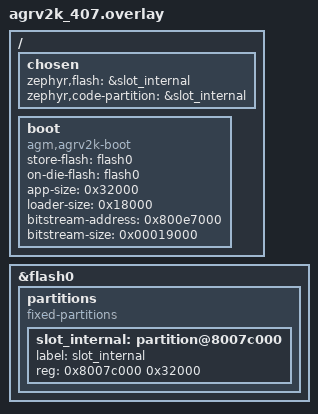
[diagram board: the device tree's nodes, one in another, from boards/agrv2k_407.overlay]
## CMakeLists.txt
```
# SPDX-License-Identifier: Apache-2.0

cmake_minimum_required(VERSION 3.28.0)
find_package(Zephyr REQUIRED HINTS $ENV{ZEPHYR_BASE})
project(usb_msc_dfu_boot)

# Reuse the upstream USB sample common code (sample_usbd.h +
# sample_usbd_init.c) instead of forking it into hal_ag32.
include(${ZEPHYR_BASE}/samples/subsys/usb/common/common.cmake)

FILE(GLOB app_sources src/*.c)
target_sources(app PRIVATE ${app_sources})
```

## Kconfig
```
# SPDX-License-Identifier: Apache-2.0

# Pull in the upstream USB sample options (SAMPLE_USBD_PID,
# SAMPLE_USBD_PRODUCT, SAMPLE_USBD_VID, ...) so prj.conf can set them.
# The `source` path is relative to $ZEPHYR_HOME/zephyr (`$ZEPHYR_BASE`).
source "samples/subsys/usb/common/Kconfig.sample_usbd"

source "Kconfig.zephyr"
```

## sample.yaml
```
# SPDX-License-Identifier: Apache-2.0
sample:
  name: usb_msc_dfu_boot
  description: |
    UF2-style USB MSC upload channel for samples/spi_boot_loader's DFU.

    A payload image (linked XIP into the loader's on-die application slot,
    like samples/spi_boot_app) that publishes a fake 64 MiB FAT16 volume so a
    host can copy a .uf2 onto a drive. Each 512 B write is parsed as a UF2
    block and its payload streamed straight into the loader's A/B store
    through the boot driver; the last block closes the MSC interface and the
    board reboots. It is the USB MSC path next to the loader's console /
    AN3155 / mcumgr upload paths, modelled on a UF2 bootloader.

    Hardware-dependent (needs the loader, the bitstream routing and a USB
    host), so the cases are build_only.
tests:
  sample.usb_msc_dfu_boot.agm_agrv2k_407:
    build_only: true
    platform_allow:
      - agrv2k_407
    integration_platforms:
      - agrv2k_407
    tags:
      - ci_build
      - hal_ag32
      - usb
      - udc
      - msc
      - dfu
      - boot
```

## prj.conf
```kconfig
# SPDX-License-Identifier: Apache-2.0
#
# UF2-style USB MSC upload channel for the spi_boot_loader DFU (agrv2k_407).
#
# This image is a payload that runs from the loader's on-die application
# slot. It publishes a fake 64 MiB FAT16 volume (src/uf2_volume.h) so a host
# mounts a drive and copies a .uf2 onto it; the sample parses the writes as a
# UF2 block stream and pushes the payload straight into the loader's A/B
# store through the boot driver's upload API (agm_boot_upload_begin/write/
# finish), closes the MSC interface and reboots. Model: a UF2 bootloader.
#
# It is the "USB MSC" upload path next to the loader's console / AN3155 /
# mcumgr paths (docs/BOOT-DFU-STATUS.md 0.1, the update section). No file
# system, no flash staging area, no image in SRAM.

# XIP into the on-die application slot the loader owns; see
# boards/agrv2k_407.overlay and samples/spi_boot_app.
CONFIG_XIP=y
CONFIG_USE_DT_CODE_PARTITION=y

# Chain-loaded image: the loader already brought the fabric up and switched
# the CPU onto the bitstream's PLL. Repeating soc.c's bring-up would
# deactivate the fabric this image is clocked from.
CONFIG_AGM_SOC_SKIP_CLOCK_INIT=y

CONFIG_SERIAL=y
CONFIG_UART_CONSOLE=y
CONFIG_PRINTK=y
CONFIG_STDOUT_CONSOLE=y

# The boot driver (drivers/misc/boot_agm.c) and the on-die flash it writes
# the stores through.
CONFIG_FLASH=y
CONFIG_FLASH_AGM=y
CONFIG_FLASH_PAGE_LAYOUT=y
CONFIG_CRC=y
CONFIG_REBOOT=y

# The USB side: a single MSC LUN backed by the sample's own fake FAT volume
# (registered at runtime with disk_access_register(), see src/main.c).
CONFIG_USB_DEVICE_STACK_NEXT=y
CONFIG_USBD_MSC_CLASS=y
CONFIG_DISK_ACCESS=y

# The UF2 block handler runs in the MSC class thread and calls into the boot
# driver's upload API (which erases/programs the store), so give that thread
# room beyond the 1024-byte default.
CONFIG_USBD_MSC_STACK_SIZE=4096

CONFIG_LOG=y
CONFIG_USBD_LOG_LEVEL_WRN=y
CONFIG_USBD_MSC_LOG_LEVEL_WRN=y
CONFIG_UDC_DRIVER_LOG_LEVEL_WRN=y

CONFIG_SAMPLE_USBD_PID=0x0008
CONFIG_SAMPLE_USBD_PRODUCT="AgRV2K USB MSC DFU (boot)"

# udc_agm is FS-only (64 B bulk MPS).
CONFIG_USBD_MAX_SPEED_FULL=y

# No HWINFO -> no iSerialNumber descriptor.
CONFIG_HWINFO=n

CONFIG_SAMPLE_USBD_SELF_POWERED=n
CONFIG_SAMPLE_USBD_REMOTE_WAKEUP=n
CONFIG_SAMPLE_USBD_MAX_POWER=50

CONFIG_MAIN_STACK_SIZE=3072
```

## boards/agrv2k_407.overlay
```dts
/* SPDX-License-Identifier: Apache-2.0 */
/*
 * usb_msc_dfu_boot -- the USB MSC upload channel for spi_boot_loader's DFU.
 *
 * Two things are configured here:
 *
 *   1. The link address: this image runs from the loader's on-die
 *      application slot, exactly like samples/spi_boot_app. Pointing
 *      /chosen/zephyr,flash at the slot partition is what moves the RISC-V
 *      link address (0x8007c000 with the default layout); the loader writes
 *      the image into that slot and jumps to it.
 *
 *   2. The boot layout: the boot driver derives every store/record offset
 *      from the boot node, so this sample has to describe the *same* layout
 *      the loader owns (samples/spi_boot_loader/boards/agrv2k_407.overlay).
 *      It uses agm_boot_upload_* on the store the loader's record does not
 *      point at, then the loader boots what it published.
 */

&flash0 {
	partitions {
		compatible = "fixed-partitions";
		#address-cells = <1>;
		#size-cells = <1>;

		slot_internal: partition@8007c000 {
			label = "slot_internal";
			reg = <0x8007c000 0x32000>;
		};
	};
};

/ {
	chosen {
		zephyr,flash = &slot_internal;
		zephyr,code-partition = &slot_internal;
	};
};

/* The loader's layout: on-die A/B (store-flash == on-die-flash), loader
 * 96 KiB, app-size 200 KiB. Keep these numbers in step with
 * samples/spi_boot_loader/boards/agrv2k_407.overlay. */
/ {
	boot: boot {
		compatible = "agm,agrv2k-boot";
		status = "okay";

		store-flash = <&flash0>;
		on-die-flash = <&flash0>;

		app-size = <0x32000>;
		loader-size = <0x18000>;

		bitstream-address = <0x800e7000>;
		bitstream-size = <0x00019000>;
	};
};
```

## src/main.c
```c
/*
 * Copyright (c) 2026 AgRV Contributors
 * SPDX-License-Identifier: Apache-2.0
 */

/*
 * usb_msc_dfu_boot -- UF2-style USB MSC DFU channel for spi_boot_loader.
 *
 * Modelled on a UF2 bootloader (RP2040 BOOTSEL, Adafruit nRF52): the device
 * stores no file system. It publishes a *fake* FAT16 volume so a host mounts
 * it and copies a .uf2 onto it, and it turns the 512-byte MSC writes into a
 * UF2 block stream:
 *
 *   sector 0, FAT sector 0   the static metadata from src/uf2_volume.h
 *   every other sector       reads back as zero (an empty FAT16 volume);
 *                            writes into the metadata region are kept in a
 *                            small RAM overlay so the volume stays coherent
 *   a write carrying a UF2 block
 *                            the payload is streamed straight into the store
 *                            the boot record does not point at
 *
 * The last block ends the update. The sample then closes the MSC interface
 * (the host sees the drive disappear), publishes through the boot driver
 * (agm_boot_upload_finish) and reboots, so the loader boots the new image.
 *
 * The image is never held in SRAM as a whole: only the 512-byte block being
 * parsed, plus whatever the boot driver keeps while it programs the store.
 *
 * Why the volume is a lie: the whole point of a UF2 bootloader is that the
 * file is not stored -- the block stream *is* the transfer, so the volume
 * can claim far more space than the device has (64 MiB here) and the host
 * never runs out. Nothing but the host's own FAT bookkeeping is ever kept.
 *
 * This is the USB MSC upload channel next to the loader's console / AN3155 /
 * mcumgr paths (docs/BOOT-DFU-STATUS.md 0.1, the update section). It runs in
 * an application rather than in the loader itself because the loader's
 * 96 KiB region is sized for the console and the two protocol servers.
 */

#include <sample_usbd.h>

#include <zephyr/device.h>
#include <zephyr/kernel.h>
#include <zephyr/drivers/disk.h>
#include <zephyr/drivers/misc/boot_agm.h>
#include <zephyr/sys/atomic.h>
#include <zephyr/sys/byteorder.h>
#include <zephyr/sys/printk.h>
#include <zephyr/sys/reboot.h>
#include <zephyr/usb/class/usbd_msc.h>
#include <zephyr/usb/usbd.h>

#include <string.h>

#include "uf2_volume.h"

#define BOOT_DEV DEVICE_DT_GET(DT_NODELABEL(boot))

/* disk_access()/MSC name of the volume; uf2_disk_ops owns every access. */
#define MSC_DISK_NAME "UF2"

/* ---- UF2 block layout (Microsoft USB Flashing Format) ---------------- */

#define UF2_MAGIC0       0x0A324655u
#define UF2_MAGIC1       0x9E5D5157u
#define UF2_MAGIC_END    0x0AB16F30u

/* Our own family id; tools/bin_to_uf2.py stamps the same value. targetAddr
 * is a *store* offset, not an absolute flash address (see the tool). */
#define UF2_FAMILY       0x41474D55u

/* tools/bin_to_uf2.py emits 256-byte payloads, so every targetAddr is a
 * multiple of 256 and the stream is trivially forward-ordered. */
#define UF2_UNIT         256u

#define UF2_OFF_MAGIC0   0u
#define UF2_OFF_MAGIC1   4u
#define UF2_OFF_FLAGS    8u
#define UF2_OFF_ADDR     12u
#define UF2_OFF_SIZE     16u
#define UF2_OFF_BLOCK    20u
#define UF2_OFF_NUMBLK   24u
#define UF2_OFF_FAMILY   28u
#define UF2_OFF_DATA     32u
#define UF2_OFF_END      508u
#define UF2_PAYLOAD_MAX  476u

/* ---- volume geometry (uf2_volume.h carries the generated numbers) ----- */

#define VOL_FAT1_START   1u
#define VOL_FAT2_START   (VOL_FAT1_START + UF2_VOL_FAT_SECTORS)
#define VOL_META_END     UF2_VOL_DATA_START

/* How many metadata sectors the host's own bookkeeping can touch before the
 * overlay gives up. One file needs its directory entry plus a FAT chain; a
 * 200 KiB image (the layout's app-size) is ~100 clusters, i.e. one FAT
 * sector per copy, so this is generous. */
#define META_SLOTS 16

struct meta_slot {
	uint32_t lba;
	bool used;
	uint8_t data[UF2_VOL_SECTOR_SIZE];
};

static struct meta_slot meta[META_SLOTS];

/* ---- update session -------------------------------------------------- */

static struct usbd_context *sample_usbd;

static struct {
	enum agm_boot_target target;
	bool active;
	uint32_t nblocks;
	uint32_t block;
	uint32_t written;
	uint32_t total;
	atomic_t ready;
	atomic_t failed;
} upd;

static void upd_reset(void)
{
	upd.active = false;
	upd.block = 0;
	upd.written = 0;
	upd.total = 0;
	upd.nblocks = 0;
	atomic_clear(&upd.ready);
	atomic_clear(&upd.failed);
}

/* The store the record does not point at; the running image stays intact. */
static enum agm_boot_target inactive_store(void)
{
	struct agm_boot_info info;

	if (agm_boot_info_get(BOOT_DEV, &info) == 0 && info.active == 0U) {
		return AGM_BOOT_TARGET_STORE_B;
	}

	return AGM_BOOT_TARGET_STORE_A;
}

static void update_fail(const char *what, uint32_t block, int err)
{
	printk("FAIL: %s at UF2 block %u (%d)\n", what, block, err);
	atomic_set(&upd.failed, 1);
}

static int update_begin(uint32_t nblocks, uint32_t addr0)
{
	uint32_t max;
	int err;

	if (addr0 != 0U) {
		update_fail("first UF2 block is not at offset 0", 0, -EINVAL);
		return -EINVAL;
	}

	upd.target = inactive_store();
	max = agm_boot_upload_max(BOOT_DEV, upd.target);
	if (nblocks * UF2_UNIT > max) {
		printk("FAIL: UF2 holds up to %u B, store %s takes %u\n",
		       nblocks * UF2_UNIT, agm_boot_target_name(upd.target), max);
		atomic_set(&upd.failed, 1);
		return -EINVAL;
	}

	err = agm_boot_upload_begin(BOOT_DEV, upd.target);
	if (err) {
		printk("FAIL: upload_begin(%s): %d\n",
		       agm_boot_target_name(upd.target), err);
		atomic_set(&upd.failed, 1);
		return err;
	}

	printk("receiving UF2: %u blocks into store %s\n", nblocks,
	       agm_boot_target_name(upd.target));
	upd.active = true;
	upd.nblocks = nblocks;
	upd.block = 0;
	upd.written = 0;

	return 0;
}

static int uf2_block_handle(const uint8_t *s)
{
	uint32_t size = sys_get_le32(s + UF2_OFF_SIZE);
	uint32_t block = sys_get_le32(s + UF2_OFF_BLOCK);
	uint32_t nblocks = sys_get_le32(s + UF2_OFF_NUMBLK);
	uint32_t family = sys_get_le32(s + UF2_OFF_FAMILY);
	uint32_t addr = sys_get_le32(s + UF2_OFF_ADDR);
	int err;

	if (family != UF2_FAMILY) {
		update_fail("UF2 family mismatch", block, -EINVAL);
		return -EIO;
	}

	if (size > UF2_PAYLOAD_MAX || nblocks == 0U || block >= nblocks) {
		update_fail("malformed UF2 block", block, -EINVAL);
		return -EIO;
	}

	if (!upd.active && update_begin(nblocks, addr) != 0) {
		return -EIO;
	}

	if (block != upd.block || addr != upd.written) {
		update_fail("UF2 block out of order", block, -EINVAL);
		return -EIO;
	}

	err = agm_boot_upload_write(BOOT_DEV, upd.target, addr,
				    s + UF2_OFF_DATA, size);
	if (err) {
		update_fail("upload_write", block, err);
		return -EIO;
	}

	upd.written += size;
	upd.block++;

	if (block + 1U == nblocks) {
		upd.total = upd.written;
		atomic_set(&upd.ready, 1);
	}

	return 0;
}

/* ---- the fake FAT16 volume ------------------------------------------- */

static bool uf2_is_block(const uint8_t *s)
{
	return sys_get_le32(s + UF2_OFF_MAGIC0) == UF2_MAGIC0 &&
	       sys_get_le32(s + UF2_OFF_MAGIC1) == UF2_MAGIC1 &&
	       sys_get_le32(s + UF2_OFF_END) == UF2_MAGIC_END;
}

static const uint8_t *meta_lookup(uint32_t lba)
{
	for (int i = 0; i < META_SLOTS; i++) {
		if (meta[i].used && meta[i].lba == lba) {
			return meta[i].data;
		}
	}

	return NULL;
}

static void meta_store(uint32_t lba, const uint8_t *data)
{
	for (int i = 0; i < META_SLOTS; i++) {
		if (meta[i].used && meta[i].lba == lba) {
			memcpy(meta[i].data, data, UF2_VOL_SECTOR_SIZE);
			return;
		}
	}

	for (int i = 0; i < META_SLOTS; i++) {
		if (!meta[i].used) {
			meta[i].used = true;
			meta[i].lba = lba;
			memcpy(meta[i].data, data, UF2_VOL_SECTOR_SIZE);
			return;
		}
	}

	/* The metadata region is tiny; running out means something is writing
	 * much more than one file's bookkeeping. Drop it (the host still sees
	 * a successful write) rather than fail the copy. */
	printk("WARN: metadata overlay full, dropping LBA %u\n", lba);
}

static int uf2_disk_status(struct disk_info *disk)
{
	ARG_UNUSED(disk);

	return DISK_STATUS_OK;
}

static int uf2_disk_init(struct disk_info *disk)
{
	ARG_UNUSED(disk);

	return 0;
}

static int uf2_disk_read(struct disk_info *disk, uint8_t *buf,
			 uint32_t lba, uint32_t count)
{
	ARG_UNUSED(disk);

	for (uint32_t i = 0; i < count; i++, lba++, buf += UF2_VOL_SECTOR_SIZE) {
		const uint8_t *src = meta_lookup(lba);

		if (src != NULL) {
			memcpy(buf, src, UF2_VOL_SECTOR_SIZE);
		} else if (lba == 0U) {
			memcpy(buf, uf2_boot_sector, UF2_VOL_SECTOR_SIZE);
		} else if (lba == VOL_FAT1_START || lba == VOL_FAT2_START) {
			memcpy(buf, uf2_fat0, UF2_VOL_SECTOR_SIZE);
		} else {
			/* Empty FAT, empty root directory, empty data area. */
			memset(buf, 0, UF2_VOL_SECTOR_SIZE);
		}
	}

	return 0;
}

static int uf2_disk_write(struct disk_info *disk, const uint8_t *buf,
			  uint32_t lba, uint32_t count)
{
	ARG_UNUSED(disk);

	for (uint32_t i = 0; i < count; i++, lba++, buf += UF2_VOL_SECTOR_SIZE) {
		if (uf2_is_block(buf)) {
			int err = uf2_block_handle(buf);

			if (err) {
				/* Fail the SCSI WRITE so the copy shows an
				 * error instead of "succeeding" silently. */
				return err;
			}

			continue;
		}

		/* The host's own FAT/directory bookkeeping: keep it so the
		 * volume stays coherent if the host reads it back. Writes into
		 * the data area that are not UF2 blocks (another file the host
		 * left behind) are not stored -- nothing reads them back. */
		if (lba < VOL_META_END) {
			meta_store(lba, buf);
		}
	}

	return 0;
}

static int uf2_disk_ioctl(struct disk_info *disk, uint8_t cmd, void *buff)
{
	ARG_UNUSED(disk);

	switch (cmd) {
	case DISK_IOCTL_GET_SECTOR_COUNT:
		*(uint32_t *)buff = UF2_VOL_SECTORS;
		break;
	case DISK_IOCTL_GET_SECTOR_SIZE:
		*(uint32_t *)buff = UF2_VOL_SECTOR_SIZE;
		break;
	case DISK_IOCTL_GET_ERASE_BLOCK_SZ:
		*(uint32_t *)buff = UF2_VOL_SECTOR_SIZE;
		break;
	case DISK_IOCTL_CTRL_SYNC:
	case DISK_IOCTL_CTRL_INIT:
	case DISK_IOCTL_CTRL_DEINIT:
		break;
	default:
		return -EINVAL;
	}

	return 0;
}

/* The MSC class may issue an erase (WRITE SAME/UNMAP); the volume has no
 * real storage behind it, so accept and ignore it. */
static int uf2_disk_erase(struct disk_info *disk, uint32_t lba, uint32_t count)
{
	ARG_UNUSED(disk);
	ARG_UNUSED(lba);
	ARG_UNUSED(count);

	return 0;
}

static const struct disk_operations uf2_disk_ops = {
	.init = uf2_disk_init,
	.status = uf2_disk_status,
	.read = uf2_disk_read,
	.write = uf2_disk_write,
	.erase = uf2_disk_erase,
	.ioctl = uf2_disk_ioctl,
};

static struct disk_info uf2_disk = {
	.name = MSC_DISK_NAME,
	.ops = &uf2_disk_ops,
};

/* MSC LUN: the host sees the fake volume as a removable drive. */
USBD_DEFINE_MSC_LUN(uf2, MSC_DISK_NAME, "AgRV", "UF2 DFU volume", "0.01");

int main(void)
{
	int err;

	printk("\n");
	printk("=========================================\n");
	printk(" usb_msc_dfu_boot: UF2-style MSC DFU\n");
	printk(" volume  : %u MiB FAT16 (fake, %u sectors)\n",
	       UF2_VOL_SECTORS * UF2_VOL_SECTOR_SIZE / (1024U * 1024U),
	       UF2_VOL_SECTORS);
	printk(" protocol: copy a .uf2 onto the drive\n");
	printk("=========================================\n");

	/* Answer the loader's trial-boot handshake, like spi_boot_app: this
	 * image's banner is its self-test. */
	err = agm_boot_trial_confirm();
	if (err == 0) {
		printk(" confirmed: this slot becomes permanent on the next boot\n");
	}

	err = disk_access_register(&uf2_disk);
	if (err) {
		printk("FAIL: disk_access_register: %d\n", err);
		return 0;
	}

	sample_usbd = sample_usbd_init_device(NULL);
	if (sample_usbd == NULL) {
		printk("FAIL: USB device init\n");
		return 0;
	}

	if (!usbd_can_detect_vbus(sample_usbd)) {
		err = usbd_enable(sample_usbd);
		if (err) {
			printk("FAIL: usbd_enable: %d\n", err);
			return 0;
		}
	}

	printk("drive is up -- copy a .uf2 onto it\n");

	while (true) {
		if (atomic_get(&upd.failed)) {
			/* Leave the record untouched and let the host retry with
			 * a correct file; the target store may be half written
			 * (same as the loader's other upload paths). */
			agm_boot_upload_abort(BOOT_DEV, upd.target);
			upd_reset();
			printk("ready for another .uf2\n");
		}

		if (atomic_get(&upd.ready)) {
			/* "Write finished" -> close the MSC interface first,
			 * exactly like a UF2 bootloader: the host sees the
			 * drive disappear, and only then does the device
			 * publish and reboot. */
			printk("UF2 complete, closing the MSC interface\n");
			usbd_disable(sample_usbd);

			err = agm_boot_upload_finish(BOOT_DEV, upd.target,
						     upd.total);
			if (err) {
				printk("FAIL: upload_finish(%u): %d\n",
				       upd.total, err);
				agm_boot_upload_abort(BOOT_DEV, upd.target);
				upd_reset();
				/* The drive was closed before publishing; bring
				 * it back so the host can retry without a reset. */
				if (usbd_enable(sample_usbd)) {
					printk("FAIL: usbd_enable\n");
				}
			} else {
				printk("PASS: %u B in store %s, rebooting\n",
				       upd.total,
				       agm_boot_target_name(upd.target));
				k_msleep(50);
				sys_reboot(SYS_REBOOT_COLD);
			}
		}

		k_msleep(50);
	}

	return 0;
}
```

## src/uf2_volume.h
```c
/*
 * Generated by tools/gen_uf2_volume.py -- do not edit.
 *
 * The fake FAT16 volume 64 MiB (AGM-DFU), as the UF2-style MSC DFU
 * sample presents it: sector 0 and the first sector of each FAT copy.
 * Every other sector of the volume reads back as zero (an empty FAT16
 * volume); see src/main.c.
 *
 * Regenerate: tools/gen_uf2_volume.py --out <this file>
 */

#ifndef UF2_VOLUME_H_
#define UF2_VOLUME_H_

#include <stdint.h>

/* Geometry the sample's disk driver has to know. */
#define UF2_VOL_SECTOR_SIZE   512u
#define UF2_VOL_SECTORS       131072u
#define UF2_VOL_FAT_SECTORS   128u
#define UF2_VOL_ROOT_SECTORS  32u
#define UF2_VOL_DATA_START    289u
#define UF2_VOL_CLUSTERS      32695u
#define UF2_VOLUME_ID         0x41474d55u

static const uint8_t uf2_boot_sector[512] = {
	0xeb, 0x3c, 0x90, 0x41, 0x47, 0x4d, 0x55, 0x46, 0x32, 0x20, 0x20, 0x00,
	0x02, 0x04, 0x01, 0x00, 0x02, 0x00, 0x02, 0x00, 0x00, 0xf8, 0x80, 0x00,
	0x3f, 0x00, 0xff, 0x00, 0x00, 0x00, 0x00, 0x00, 0x00, 0x00, 0x02, 0x00,
	0x80, 0x00, 0x29, 0x55, 0x4d, 0x47, 0x41, 0x41, 0x47, 0x4d, 0x2d, 0x44,
	0x46, 0x55, 0x20, 0x20, 0x20, 0x20, 0x46, 0x41, 0x54, 0x31, 0x36, 0x20,
	0x20, 0x20, 0x00, 0x00, 0x00, 0x00, 0x00, 0x00, 0x00, 0x00, 0x00, 0x00,
	0x00, 0x00, 0x00, 0x00, 0x00, 0x00, 0x00, 0x00, 0x00, 0x00, 0x00, 0x00,
	0x00, 0x00, 0x00, 0x00, 0x00, 0x00, 0x00, 0x00, 0x00, 0x00, 0x00, 0x00,
	0x00, 0x00, 0x00, 0x00, 0x00, 0x00, 0x00, 0x00, 0x00, 0x00, 0x00, 0x00,
	0x00, 0x00, 0x00, 0x00, 0x00, 0x00, 0x00, 0x00, 0x00, 0x00, 0x00, 0x00,
	0x00, 0x00, 0x00, 0x00, 0x00, 0x00, 0x00, 0x00, 0x00, 0x00, 0x00, 0x00,
	0x00, 0x00, 0x00, 0x00, 0x00, 0x00, 0x00, 0x00, 0x00, 0x00, 0x00, 0x00,
	0x00, 0x00, 0x00, 0x00, 0x00, 0x00, 0x00, 0x00, 0x00, 0x00, 0x00, 0x00,
	0x00, 0x00, 0x00, 0x00, 0x00, 0x00, 0x00, 0x00, 0x00, 0x00, 0x00, 0x00,
	0x00, 0x00, 0x00, 0x00, 0x00, 0x00, 0x00, 0x00, 0x00, 0x00, 0x00, 0x00,
	0x00, 0x00, 0x00, 0x00, 0x00, 0x00, 0x00, 0x00, 0x00, 0x00, 0x00, 0x00,
	0x00, 0x00, 0x00, 0x00, 0x00, 0x00, 0x00, 0x00, 0x00, 0x00, 0x00, 0x00,
	0x00, 0x00, 0x00, 0x00, 0x00, 0x00, 0x00, 0x00, 0x00, 0x00, 0x00, 0x00,
	0x00, 0x00, 0x00, 0x00, 0x00, 0x00, 0x00, 0x00, 0x00, 0x00, 0x00, 0x00,
	0x00, 0x00, 0x00, 0x00, 0x00, 0x00, 0x00, 0x00, 0x00, 0x00, 0x00, 0x00,
	0x00, 0x00, 0x00, 0x00, 0x00, 0x00, 0x00, 0x00, 0x00, 0x00, 0x00, 0x00,
	0x00, 0x00, 0x00, 0x00, 0x00, 0x00, 0x00, 0x00, 0x00, 0x00, 0x00, 0x00,
	0x00, 0x00, 0x00, 0x00, 0x00, 0x00, 0x00, 0x00, 0x00, 0x00, 0x00, 0x00,
	0x00, 0x00, 0x00, 0x00, 0x00, 0x00, 0x00, 0x00, 0x00, 0x00, 0x00, 0x00,
	0x00, 0x00, 0x00, 0x00, 0x00, 0x00, 0x00, 0x00, 0x00, 0x00, 0x00, 0x00,
	0x00, 0x00, 0x00, 0x00, 0x00, 0x00, 0x00, 0x00, 0x00, 0x00, 0x00, 0x00,
	0x00, 0x00, 0x00, 0x00, 0x00, 0x00, 0x00, 0x00, 0x00, 0x00, 0x00, 0x00,
	0x00, 0x00, 0x00, 0x00, 0x00, 0x00, 0x00, 0x00, 0x00, 0x00, 0x00, 0x00,
	0x00, 0x00, 0x00, 0x00, 0x00, 0x00, 0x00, 0x00, 0x00, 0x00, 0x00, 0x00,
	0x00, 0x00, 0x00, 0x00, 0x00, 0x00, 0x00, 0x00, 0x00, 0x00, 0x00, 0x00,
	0x00, 0x00, 0x00, 0x00, 0x00, 0x00, 0x00, 0x00, 0x00, 0x00, 0x00, 0x00,
	0x00, 0x00, 0x00, 0x00, 0x00, 0x00, 0x00, 0x00, 0x00, 0x00, 0x00, 0x00,
	0x00, 0x00, 0x00, 0x00, 0x00, 0x00, 0x00, 0x00, 0x00, 0x00, 0x00, 0x00,
	0x00, 0x00, 0x00, 0x00, 0x00, 0x00, 0x00, 0x00, 0x00, 0x00, 0x00, 0x00,
	0x00, 0x00, 0x00, 0x00, 0x00, 0x00, 0x00, 0x00, 0x00, 0x00, 0x00, 0x00,
	0x00, 0x00, 0x00, 0x00, 0x00, 0x00, 0x00, 0x00, 0x00, 0x00, 0x00, 0x00,
	0x00, 0x00, 0x00, 0x00, 0x00, 0x00, 0x00, 0x00, 0x00, 0x00, 0x00, 0x00,
	0x00, 0x00, 0x00, 0x00, 0x00, 0x00, 0x00, 0x00, 0x00, 0x00, 0x00, 0x00,
	0x00, 0x00, 0x00, 0x00, 0x00, 0x00, 0x00, 0x00, 0x00, 0x00, 0x00, 0x00,
	0x00, 0x00, 0x00, 0x00, 0x00, 0x00, 0x00, 0x00, 0x00, 0x00, 0x00, 0x00,
	0x00, 0x00, 0x00, 0x00, 0x00, 0x00, 0x00, 0x00, 0x00, 0x00, 0x00, 0x00,
	0x00, 0x00, 0x00, 0x00, 0x00, 0x00, 0x00, 0x00, 0x00, 0x00, 0x00, 0x00,
	0x00, 0x00, 0x00, 0x00, 0x00, 0x00, 0x55, 0xaa,
};

static const uint8_t uf2_fat0[512] = {
	0xf8, 0xff, 0xff, 0xff, 0x00, 0x00, 0x00, 0x00, 0x00, 0x00, 0x00, 0x00,
	0x00, 0x00, 0x00, 0x00, 0x00, 0x00, 0x00, 0x00, 0x00, 0x00, 0x00, 0x00,
	0x00, 0x00, 0x00, 0x00, 0x00, 0x00, 0x00, 0x00, 0x00, 0x00, 0x00, 0x00,
	0x00, 0x00, 0x00, 0x00, 0x00, 0x00, 0x00, 0x00, 0x00, 0x00, 0x00, 0x00,
	0x00, 0x00, 0x00, 0x00, 0x00, 0x00, 0x00, 0x00, 0x00, 0x00, 0x00, 0x00,
	0x00, 0x00, 0x00, 0x00, 0x00, 0x00, 0x00, 0x00, 0x00, 0x00, 0x00, 0x00,
	0x00, 0x00, 0x00, 0x00, 0x00, 0x00, 0x00, 0x00, 0x00, 0x00, 0x00, 0x00,
	0x00, 0x00, 0x00, 0x00, 0x00, 0x00, 0x00, 0x00, 0x00, 0x00, 0x00, 0x00,
	0x00, 0x00, 0x00, 0x00, 0x00, 0x00, 0x00, 0x00, 0x00, 0x00, 0x00, 0x00,
	0x00, 0x00, 0x00, 0x00, 0x00, 0x00, 0x00, 0x00, 0x00, 0x00, 0x00, 0x00,
	0x00, 0x00, 0x00, 0x00, 0x00, 0x00, 0x00, 0x00, 0x00, 0x00, 0x00, 0x00,
	0x00, 0x00, 0x00, 0x00, 0x00, 0x00, 0x00, 0x00, 0x00, 0x00, 0x00, 0x00,
	0x00, 0x00, 0x00, 0x00, 0x00, 0x00, 0x00, 0x00, 0x00, 0x00, 0x00, 0x00,
	0x00, 0x00, 0x00, 0x00, 0x00, 0x00, 0x00, 0x00, 0x00, 0x00, 0x00, 0x00,
	0x00, 0x00, 0x00, 0x00, 0x00, 0x00, 0x00, 0x00, 0x00, 0x00, 0x00, 0x00,
	0x00, 0x00, 0x00, 0x00, 0x00, 0x00, 0x00, 0x00, 0x00, 0x00, 0x00, 0x00,
	0x00, 0x00, 0x00, 0x00, 0x00, 0x00, 0x00, 0x00, 0x00, 0x00, 0x00, 0x00,
	0x00, 0x00, 0x00, 0x00, 0x00, 0x00, 0x00, 0x00, 0x00, 0x00, 0x00, 0x00,
	0x00, 0x00, 0x00, 0x00, 0x00, 0x00, 0x00, 0x00, 0x00, 0x00, 0x00, 0x00,
	0x00, 0x00, 0x00, 0x00, 0x00, 0x00, 0x00, 0x00, 0x00, 0x00, 0x00, 0x00,
	0x00, 0x00, 0x00, 0x00, 0x00, 0x00, 0x00, 0x00, 0x00, 0x00, 0x00, 0x00,
	0x00, 0x00, 0x00, 0x00, 0x00, 0x00, 0x00, 0x00, 0x00, 0x00, 0x00, 0x00,
	0x00, 0x00, 0x00, 0x00, 0x00, 0x00, 0x00, 0x00, 0x00, 0x00, 0x00, 0x00,
	0x00, 0x00, 0x00, 0x00, 0x00, 0x00, 0x00, 0x00, 0x00, 0x00, 0x00, 0x00,
	0x00, 0x00, 0x00, 0x00, 0x00, 0x00, 0x00, 0x00, 0x00, 0x00, 0x00, 0x00,
	0x00, 0x00, 0x00, 0x00, 0x00, 0x00, 0x00, 0x00, 0x00, 0x00, 0x00, 0x00,
	0x00, 0x00, 0x00, 0x00, 0x00, 0x00, 0x00, 0x00, 0x00, 0x00, 0x00, 0x00,
	0x00, 0x00, 0x00, 0x00, 0x00, 0x00, 0x00, 0x00, 0x00, 0x00, 0x00, 0x00,
	0x00, 0x00, 0x00, 0x00, 0x00, 0x00, 0x00, 0x00, 0x00, 0x00, 0x00, 0x00,
	0x00, 0x00, 0x00, 0x00, 0x00, 0x00, 0x00, 0x00, 0x00, 0x00, 0x00, 0x00,
	0x00, 0x00, 0x00, 0x00, 0x00, 0x00, 0x00, 0x00, 0x00, 0x00, 0x00, 0x00,
	0x00, 0x00, 0x00, 0x00, 0x00, 0x00, 0x00, 0x00, 0x00, 0x00, 0x00, 0x00,
	0x00, 0x00, 0x00, 0x00, 0x00, 0x00, 0x00, 0x00, 0x00, 0x00, 0x00, 0x00,
	0x00, 0x00, 0x00, 0x00, 0x00, 0x00, 0x00, 0x00, 0x00, 0x00, 0x00, 0x00,
	0x00, 0x00, 0x00, 0x00, 0x00, 0x00, 0x00, 0x00, 0x00, 0x00, 0x00, 0x00,
	0x00, 0x00, 0x00, 0x00, 0x00, 0x00, 0x00, 0x00, 0x00, 0x00, 0x00, 0x00,
	0x00, 0x00, 0x00, 0x00, 0x00, 0x00, 0x00, 0x00, 0x00, 0x00, 0x00, 0x00,
	0x00, 0x00, 0x00, 0x00, 0x00, 0x00, 0x00, 0x00, 0x00, 0x00, 0x00, 0x00,
	0x00, 0x00, 0x00, 0x00, 0x00, 0x00, 0x00, 0x00, 0x00, 0x00, 0x00, 0x00,
	0x00, 0x00, 0x00, 0x00, 0x00, 0x00, 0x00, 0x00, 0x00, 0x00, 0x00, 0x00,
	0x00, 0x00, 0x00, 0x00, 0x00, 0x00, 0x00, 0x00, 0x00, 0x00, 0x00, 0x00,
	0x00, 0x00, 0x00, 0x00, 0x00, 0x00, 0x00, 0x00, 0x00, 0x00, 0x00, 0x00,
	0x00, 0x00, 0x00, 0x00, 0x00, 0x00, 0x00, 0x00,
};

#endif /* UF2_VOLUME_H_ */
```
